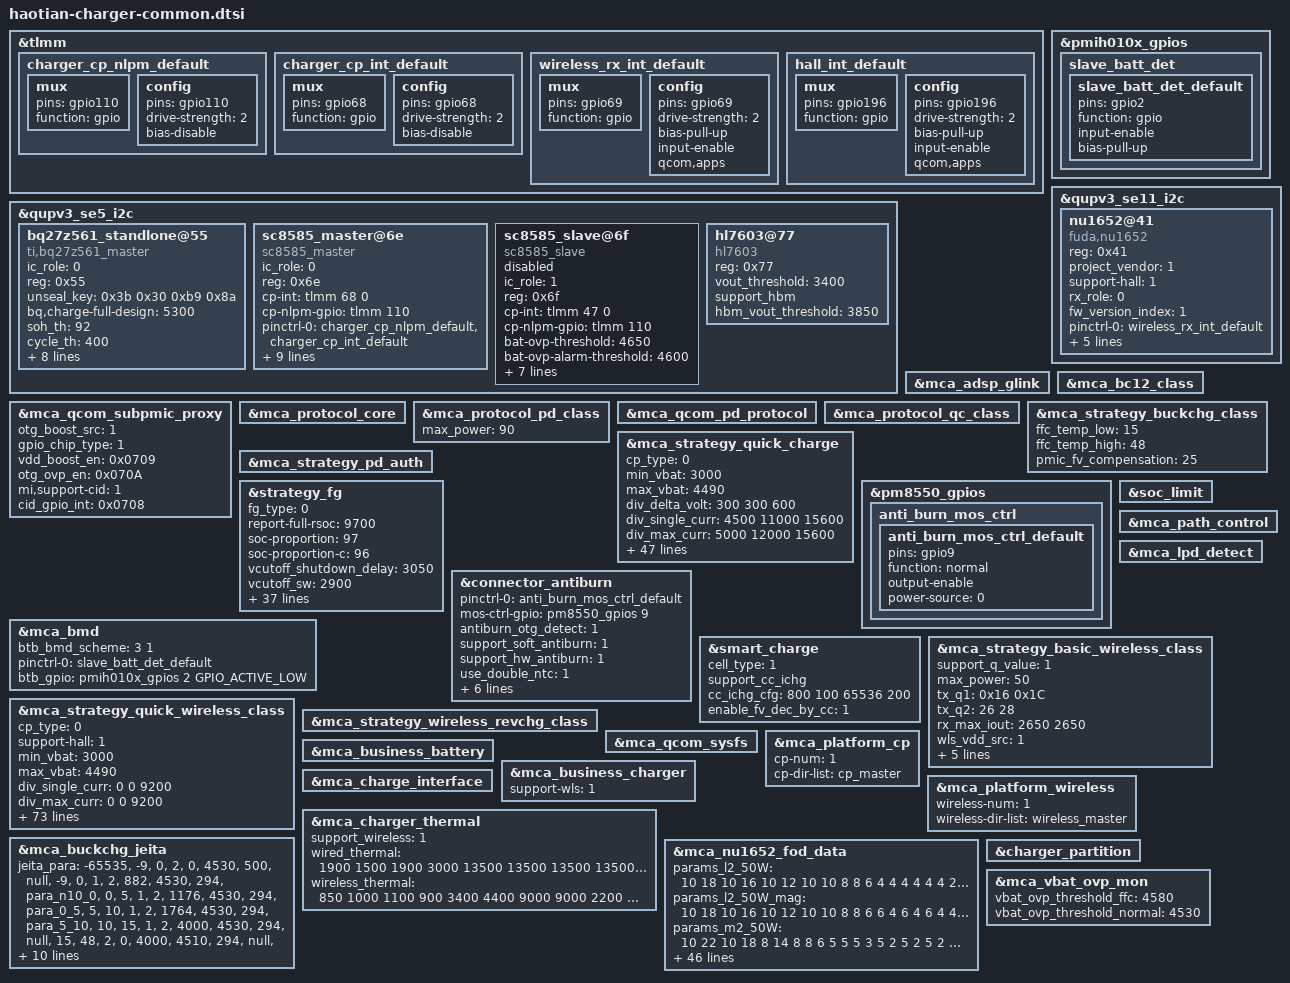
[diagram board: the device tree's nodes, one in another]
#include "mca.dtsi"

&tlmm {
	charger_cp_nlpm_default: charger_cp_nlpm_default {
		mux {
			pins = "gpio110";
			function = "gpio";
		};
		config {
			pins = "gpio110";
			drive-strength = <2>;   /* 2 mA */
			bias-disable;
		};
	};

	charger_cp_int_default: charger_cp_int_default {
		mux {
			pins = "gpio68";
			function = "gpio";
		};
		config {
			pins = "gpio68";
			drive-strength = <2>;   /* 2 mA */
			bias-disable;
		};
	};

	wireless_rx_int_default: wireless_rx_int_default {
		mux {
			pins = "gpio69";
			function = "gpio";
		};

		config {
			pins = "gpio69";
			drive-strength = <2>;
			bias-pull-up;
			input-enable;
			qcom,apps;
		};
	};

	hall_int_default: hall_int_default {
		mux {
			pins = "gpio196";
			function = "gpio";
		};

		config {
			pins = "gpio196";
			drive-strength = <2>;
			bias-pull-up;
			input-enable;
			qcom,apps;
		};
	};
};

&pmih010x_gpios {
	slave_batt_det {
		slave_batt_det_default: slave_batt_det_default {
			pins = "gpio2";
			function = "gpio";
			input-enable;
			bias-pull-up;
		};
	};
};


&qupv3_se5_i2c {
	status = "ok";
	#address-cells = <1>;
	#size-cells = <0>;
	bq27z561_standlone@55 {
		compatible = "ti,bq27z561_master";
		ic_role = <0>;
		reg = <0x55>;
		unseal_key = /bits/ 8 <0x3b 0x30 0xb9 0x8a>;
		bq,charge-full-design = <5300>;
		soh_th = <92>;
		cycle_th = <400>;
		cycle_step = <50>;
		resistance-id = <100000>;
		support-voltage-record-level;
		version_number = /bits/ 8 <0x44>;
		start_byte_address = /bits/ 8 <8>;
		byte_length = /bits/ 8 <8>;
		record_voltage = /bits/ 8 <0x86 0x0B 0x4E 0x0C 0x0C 0x0D 0x88 0x13>;
		status = "ok";
	};

	sc8585_master@6e {
		compatible = "sc8585_master";
		status = "ok";
		ic_role = <0>;
		reg = <0x6e>;
		cp-int= <&tlmm 68 0>;
		cp-nlpm-gpio = <&tlmm 110 0x00>;
		pinctrl-names = "default";
		pinctrl-0 = <&charger_cp_nlpm_default>, <&charger_cp_int_default>;
		bat-ovp-threshold = <4700>;
		bat-ovp-alarm-threshold = <4650>;
		bus-ovp-threshold = <21000 12000 6000>;
		usb-ovp-threshold = <21000 14000 7500>;
		bus-ocp-threshold = <5000 5500 5000>;
		wpc-ovp-threshold = <21000>;
		out-ovp-threshold = <5000>;
		pmid2-uvp-threshold = <100>;
		pmid2-ovp-threshold = <600>;
	};

	sc8585_slave@6f {
		compatible = "sc8585_slave";
		status = "disabled"; // O2 changed to use one cp since P1.1
		ic_role = <1>;
		reg = <0x6f>;
		cp-int= <&tlmm 47 0>;
		cp-nlpm-gpio = <&tlmm 110 0x00>;
		bat-ovp-threshold = <4650>;
		bat-ovp-alarm-threshold = <4600>;
		bus-ovp-threshold = <21000 12000 6000>;
		usb-ovp-threshold = <21000 14000 7500>;
		bus-ocp-threshold = <3500 5000 3500>;
		wpc-ovp-threshold = <21000>;
		out-ovp-threshold = <5000>;
		pmid2-uvp-threshold = <100>;
		pmid2-ovp-threshold = <600>;
	};

	hl7603@77 {
		compatible = "hl7603";
		reg = <0x77>;
		vout_threshold = <3400>;
		support_hbm;
		hbm_vout_threshold = <3850>;
	};
};

&qupv3_se11_i2c {
	status = "ok";
	#address-cells = <1>;
	#size-cells = <0>;
	nu1652@41 {
		compatible = "fuda,nu1652";
		reg = <0x41>;
		project_vendor = <1>;
		support-hall = <1>;
		rx_role = <0>;
		fw_version_index = <1>;
		pinctrl-names = "rx_int_pull_up", "hall_int_pull_up";
		pinctrl-0 = <&wireless_rx_int_default>;
		pinctrl-1 = <&hall_int_default>;
		rx-int = <&tlmm 69 0x00>;
		pwr-det-int = <&tlmm 81 0x00>;
		sleep-rx-gpio = <&tlmm 94 0x00>;
		hall-int2 = <&tlmm 196 0x00>;
	};
};

&mca_adsp_glink {
	status = "ok";
};

&mca_bc12_class {
	status = "ok";
};

&mca_qcom_subpmic_proxy {
	status = "ok";
	otg_boost_src = <1>;
	gpio_chip_type = <1>;
	vdd_boost_en = <0x0709>;
	otg_ovp_en = <0x070A>;
	mi,support-cid = <1>;
	cid_gpio_int = <0x0708>;
};

&mca_protocol_core {
	status = "ok";
};

&mca_protocol_pd_class {
	status = "ok";
	max_power = <90>;
};

&mca_qcom_pd_protocol {
	status = "ok";
};

&mca_protocol_qc_class {
	status = "ok";
};

&mca_strategy_buckchg_class {
	status = "ok";
	ffc_temp_low = <15>;
	ffc_temp_high = <48>;
	pmic_fv_compensation = <25>;
};

&mca_strategy_quick_charge {
	status = "ok";
	cp_type = <0>;
	min_vbat = <3000>;
	max_vbat = <4490>;
	div_delta_volt = <300 300 600>;
	div_single_curr = <4500 11000 15600>;
	div_max_curr = <5000 12000 15600>;
	ibus_compensation = <600 300 200>;
	max_power = <90000>;
	qc_normal_charge_fv = <4510>;
	pps_taper_vol_hys = <2>;
	pps_taper_fcc_thr = <2100>;
	hardware_cv = <1>;
	support_mode = <6>;
	support_cp_vfc = <1>;
	support_curr_monitor = <1>;
	curr_monitor_time_s = <130>;

	vstep_para =
		"1", "2000", "2",
		"2", "2000", "4",
		"4", "8000", "20",
		"4", "4000", "15",
		"4", "1500", "5",
		"4", "1000", "2",
		"4", "600", "2";

	batt_para =
		"0", "atl", "batt_para_atl",
		"0", "lwn", "batt_para_lwn";

	/* -------------------- batt_para_atl start -------------------- */
	/* temp_low, temp_high, low_temp_hys, high_temp_hys, max_current, volt_para_name stage_para_name */
	batt_para_atl =
		"-65535", "10", "0", "0", "0", "4100", "4100", "null", "null", "null", "null",
		"10", "15", "0", "0", "7056", "4530", "4530", "normal_para_atl_10_15", "null", "null", "null",
		"15", "48", "2", "2", "15600", "4510", "4580", "normal_para_atl_15_48", "ffc_para_atl_15_48", "null", "ffc_stage_atl_15_48",
		"48", "65535", "0", "0", "0", "4100", "4100", "null", "null", "null", "null";

	normal_para_atl_10_15 =
		"4200", "7056", "5880",
		"4523", "5880", "800";

	normal_para_atl_15_48 =
		"4270", "15600", "7056",
		"4503", "7056", "800";
	ffc_para_atl_15_48 =
		"4270", "15600", "12400",
		"4300", "12400", "10584",
		"4400", "10584", "8820",
		"4500", "8820", "7056",
		"4573", "7056", "2000";
	ffc_stage_atl_15_48 = <0 0 0 0 0 0 0 0 0 0>;
	/* -------------------- batt_para_atl end -------------------- */

	/* -------------------- batt_para_lwn start -------------------- */
	/* temp_low, temp_high, low_temp_hys, high_temp_hys, max_current, volt_para_name stage_para_name */
	batt_para_lwn =
		"-65535", "10", "0", "0", "0", "4100", "4100", "null", "null", "null", "null",
		"10", "15", "0", "0", "7056", "4530", "4530", "normal_para_lwn_10_15", "null", "null", "null",
		"15", "48", "2", "2", "15600", "4510", "4580", "normal_para_lwn_15_48", "ffc_para_lwn_15_48", "null", "ffc_stage_lwn_15_48",
		"48", "65535", "0", "0", "0", "4100", "4100", "null", "null", "null", "null";

	normal_para_lwn_10_15 =
		"4200", "7056", "5880",
		"4523", "5880", "800";

	normal_para_lwn_15_48 =
		"4210", "15600", "7056",
		"4503", "7056", "800";
	ffc_para_lwn_15_48 =
		"4210", "15600", "12400",
		"4300", "12400", "10584",
		"4400", "10584", "8820",
		"4500", "8820", "7056",
		"4573", "7056", "2000";
	ffc_stage_lwn_15_48 = <0 0 0 0 0 0 0 0 0 0>;
	/* -------------------- batt_para_lwn end -------------------- */
};

&mca_strategy_pd_auth {
	status = "ok";
};


&strategy_fg {
	status = "ok";
	fg_type = <0>;
	report-full-rsoc = <9700>;
	soc-proportion = <97>;
	soc-proportion-c = <96>;
	vcutoff_shutdown_delay = <3050>;
	vcutoff_sw = <2900>;
	vcutoff_fw = <3050>;
	support-vpack-low-shutdown;
	support-cc-vcutoff;
	/*temp_low, temp_high, low_temp_hys, high_temp_hys, vterm_para_name*/
	cc_vcutoff_cfg =
		"-65535", "0", "0", "2", "cc_para0",
		"0", "65535", "2", "0", "cc_para1";
	cc_para0 =
		"600", "2900", "2850", "2750",
		"1200", "3150", "3100", "2900",
		"65535", "3250", "3200","2900";
	cc_para1 =
		"200", "2900", "2850", "2750",
		"600", "3050", "3050", "2900",
		"1200", "3250", "3250", "2900",
		"65535", "3340", "3340", "2900";
	support-dod-vcutoff;
	weight = <36 21 14>;
	/*temp_low, temp_high, low_temp_hys, high_temp_hys, vterm_para_name*/
	dod_vcutoff_cfg =
		"-65535", "-6", "0", "2", "dod_para0",
		"-6", "0", "2", "2", "dod_para1",
		"0", "10", "2", "2", "dod_para2",
		"10", "60", "2", "2", "dod_para3",
		"60", "65535", "2", "0", "dod_para4";
	/*dod_count, vterm_fw, vterm_shutdown_delay, vempty*/
	dod_para0 =
		"32", "2900", "2850", "2750",
		"146", "2950", "2900", "2800",
		"176", "3050", "3000", "2900",
		"65535", "3150", "3100", "2900";
	dod_para1 =
		"32", "2900", "2850","2750",
		"146", "3050", "3000","2900",
		"176", "3150", "3100","2900",
		"65535", "3250", "3250","2900";
	dod_para2 =
		"14", "2900", "2850","2750",
	 	"32", "3050", "3050","2900",
		"146", "3150", "3150","2900",
		"176", "3250", "3250","2900",
		"65535", "3340", "3340","2900";
	dod_para3 =
		"14", "2900", "2850","2750",
	 	"32", "3050", "3050","2900",
		"146", "3250", "3250","2900",
		"176", "3340", "3340","2900",
		"65535", "3400", "3400","2900";
	dod_para4 =
		"65535", "3430", "3430","2900";
	adapt_power = <90>;
	model-name = "O2_6100mah_90w";
	model-name-global = "O2_6100mah_90w";
	charge-full-design = <6100>;
	charge-full-design-gl = <6100>;
	support_dtpt = <1>;
	support-lossless-rechg = <1>;
	lossless_rechg_cfg = <15 47 300>;
};

&pm8550_gpios {
        anti_burn_mos_ctrl {
                anti_burn_mos_ctrl_default: anti_burn_mos_ctrl_default {
                        pins = "gpio9";
                        function = "normal";
                        output-enable;
                        //drive-strength = <2>;
                        power-source = <0>;
                };
        };
};

&connector_antiburn {
	status = "ok";
	pinctrl-names = "default";
	pinctrl-0 = <&anti_burn_mos_ctrl_default>;
	mos-ctrl-gpio = <&pm8550_gpios 9 0>;
	antiburn_otg_detect = <1>;
	support_soft_antiburn = <1>;
	support_hw_antiburn = <1>;
	use_double_ntc = <1>;
	monitor_interval = <1000>;
	thermal-zone-name = "conn_therm";
	thermal-zone-name2 = "conn_therm2";
	max_temp_increase_rate = <4>; /*ntc temperature increase speed per second.*/
	otg_boost_src = <2>;   //BOOST_SRC_EXTERNAL
	en_src = <0>;      //OTG_EN_BOOST
        //thermal-board-temp-name = "board_sensor_therm";
};

&mca_bmd {
	status = "ok";
	btb_bmd_scheme = <3 1>;
	pinctrl-names = "default";
	pinctrl-0 = <&slave_batt_det_default>;
	btb_gpio = <&pmih010x_gpios 2 GPIO_ACTIVE_LOW>;
};

&smart_charge {
	status = "ok";
	cell_type = <1>;
	support_cc_ichg;
	cc_ichg_cfg = </* cyclecount delta_ichg*/
	800 100
	65536 200>;
	enable_fv_dec_by_cc = <1>;
};

&soc_limit {
	status = "ok";
};

&mca_path_control {
	status = "ok";
};

&mca_lpd_detect {
	status = "ok";
};

&mca_strategy_basic_wireless_class {
	status = "ok";
	support_q_value = <1>;
	max_power = <50>;
	//low_inductance_tx_50w, low_inductance_tx_80w
	tx_q1 = /bits/ 8 <0x16 0x1C>;
	tx_q2 = <26 28>;
	rx_max_iout = <2650 2650>;
	wls_vdd_src = <1>;
	ffc_temp_low = <15>;
	ffc_temp_high = <48>;
	support-hall = <1>;
	phone_icl = <150>;
	pmic_fv_compensation = <15>;
};

&mca_strategy_quick_wireless_class {
	status = "ok";
	cp_type = <0>;
	support-hall = <1>;
	min_vbat = <3000>;
	max_vbat = <4490>;
	div_single_curr = <0 0 9200>;
	div_max_curr = <0 0 9200>;
	batt_para =
		"0", "atl", "batt_para_atl",
		"0", "lwn", "batt_para_lwn";

	/* -------------------- batt_para_atl start -------------------- */
	/* temp_low, temp_high, low_temp_hys, high_temp_hys, max_current, volt_para_name stage_para_name */
	batt_para_atl =
		"-65535", "10", "0", "0", "0", "4100", "4100", "null", "null", "null", "null",
		"10", "15", "0", "0", "7056", "4530", "4530", "normal_para_atl_10_15", "null", "null", "null",
		"15", "35", "2", "2", "15600", "4510", "4580", "normal_para_atl_15_35", "ffc_para_atl_15_35", "null", "ffc_stage_atl_15_35",
		"35", "40", "2", "2", "15600", "4510", "4580", "normal_para_atl_35_40", "ffc_para_atl_35_40", "null", "ffc_stage_atl_35_40",
		"40", "48", "2", "2", "15600", "4510", "4580", "normal_para_atl_40_48", "ffc_para_atl_40_48", "null", "ffc_stage_atl_40_48",
		"48", "65535", "0", "0", "0", "4100", "4100", "null", "null", "null", "null";

	normal_para_atl_10_15 =
		"4200", "7056", "5880",
		"4530", "5880", "800";

	normal_para_atl_15_35 =
		"4270", "15600", "7056",
		"4510", "7056", "800";
	ffc_para_atl_15_35 =
		"4270", "15600", "12400",
		"4300", "12400", "10584",
		"4400", "10584", "8820",
		"4500", "8820", "7056",
		"4570", "7056", "2300";
	ffc_stage_atl_15_35 = <0 1 0 0 0 0 0 0 0 0>;

	normal_para_atl_35_40 =
		"4270", "15600", "7056",
		"4510", "7056", "800";
	ffc_para_atl_35_40 =
		"4270", "15600", "12400",
		"4300", "12400", "10584",
		"4400", "10584", "8820",
		"4500", "8820", "7056",
		"4570", "7056", "3000";
	ffc_stage_atl_35_40 = <0 1 0 0 0 0 0 0 0 0>;

	normal_para_atl_40_48 =
		"4270", "15600", "7056",
		"4510", "7056", "800";
	ffc_para_atl_40_48 =
		"4270", "15600", "12400",
		"4300", "12400", "10584",
		"4400", "10584", "8820",
		"4500", "8820", "7056",
		"4570", "7056", "3000";
	ffc_stage_atl_40_48 = <0 1 0 0 0 0 0 0 0 0>;
	/* -------------------- batt_para_atl end -------------------- */

	/* -------------------- batt_para_lwn start -------------------- */
	/* temp_low, temp_high, low_temp_hys, high_temp_hys, max_current, volt_para_name stage_para_name */
	batt_para_lwn =
		"-65535", "10", "0", "0", "0", "4100", "4100", "null", "null", "null", "null",
		"10", "15", "0", "0", "7056", "4530", "4530", "normal_para_lwn_10_15", "null", "null", "null",
		"15", "35", "2", "2", "15600", "4510", "4580", "normal_para_lwn_15_35", "ffc_para_lwn_15_35", "null", "ffc_stage_lwn_15_35",
		"35", "40", "2", "2", "15600", "4510", "4580", "normal_para_lwn_35_40", "ffc_para_lwn_35_40", "null", "ffc_stage_lwn_35_40",
		"40", "48", "2", "2", "15600", "4510", "4580", "normal_para_lwn_40_48", "ffc_para_lwn_40_48", "null", "ffc_stage_lwn_40_48",
		"48", "65535", "0", "0", "0", "4100", "4100", "null", "null", "null", "null";

	normal_para_lwn_10_15 =
		"4200", "7056", "5880",
		"4530", "5880", "800";

	normal_para_lwn_15_35 =
		"4210", "15600", "7056",
		"4510", "7056", "800";
	ffc_para_lwn_15_35 =
		"4210", "15600", "12400",
		"4300", "12400", "10584",
		"4400", "10584", "8820",
		"4500", "8820", "7056",
		"4570", "7056", "2300";
	ffc_stage_lwn_15_35 = <0 1 0 0 0 0 0 0 0 0>;

	normal_para_lwn_35_40 =
		"4210", "15600", "7056",
		"4510", "7056", "800";
	ffc_para_lwn_35_40 =
		"4210", "15600", "12400",
		"4300", "12400", "10584",
		"4400", "10584", "8820",
		"4500", "8820", "7056",
		"4570", "7056", "3000";
	ffc_stage_lwn_35_40 = <0 1 0 0 0 0 0 0 0 0>;

	normal_para_lwn_40_48 =
		"4210", "15600", "7056",
		"4510", "7056", "800";
	ffc_para_lwn_40_48 =
		"4210", "15600", "12400",
		"4300", "12400", "10584",
		"4400", "10584", "8820",
		"4500", "8820", "7056",
		"4570", "7056", "3000";
	ffc_stage_lwn_40_48 = <0 1 0 0 0 0 0 0 0 0>;
	/* -------------------- batt_para_lwn end -------------------- */

	vstep_para =
		"1", "2000", "2",
		"2", "2000", "4",
		"4", "4000", "25",
		"4", "3000", "25",
		"4", "2000", "6",
		"4", "1000", "3",
		"4", "500", "2",
		"4", "200", "1";
};

&mca_strategy_wireless_revchg_class{
	status = "ok";
};

&mca_qcom_sysfs {
	status = "ok";
};

&mca_business_battery {
	status = "ok";
};

&mca_business_charger {
	support-wls = <1>;
	status = "ok";
};

&mca_platform_cp {
	status = "ok";
	cp-num = <1>;
	cp-dir-list = "cp_master";
};

&mca_platform_wireless {
	status = "ok";
	wireless-num = <1>;
	wireless-dir-list = "wireless_master";
};

&mca_charge_interface
{
	status = "ok";
};

&mca_charger_thermal
{
	status = "ok";
	support_wireless = <1>;
	// wired_sic_select = "atl", "lwn";
	/* 5v_in 9v_in 5v_ichg 9v_ichg div1_single div1_multi div2_single div2_multi div4_single div4_multi*/
	wired_thermal = <
		1900 1500 1900 3000 13500 13500 13500 13500 13500 13500 /* level 1 */
		1900 1500 1900 3000 11000 11000 11000 11000 11000 11000 /* level 2 */
		1900 1500 1900 3000 9000  9000  9000  9000  9000  9000  /* level 3 */
		1900 1450 1900 3000 8000  8000  8000  8000  8000  8000  /* level 4 */
		1900 1400 1900 3000 7000  7000  7000  7000  7000  7000  /* level 5 */
		1900 1350 1900 2800 6000  6000  6000  6000  6000  6000  /* level 6 */
		1900 1300 1900 2600 5000  5000  5000  5000  5000  5000  /* level 7 */
		1900 1150 1900 2310 4000  4000  4000  4000  4000  4000  /* level 8 */
		1700 1100 1700 2200 3500  3500  3500  3500  3500  3500  /* level 9 */
		1600 1000 1600 2000 3000  3000  3000  3000  3000  3000  /* level 10 */
		1400 900  1500 2000 2500  2500  2500  2500  2500  2500  /* level 11 */
		1200 850  1500 2000 2000  2000  2000  2000  2000  2000  /* level 12 */
		1100 750  1500 1500 1500  1500  1500  1500  1500  1500  /* level 13 */
		1100 650  1000 1000 1000  1000  1000  1000  1000  1000  /* level 14 */
		1100 600  500  500  500   500   500   500   500   500   /* level 15 */
	>;
	/* bpp_in bpp_qc2 bpp_qc3 epp_in cp_20w cp_30w cp_50w cp_80w voice_box magnet_30w*/
	wireless_thermal = <
	850 1000 1100 900 3400 4400 9000 9000 2200 4400 /* level 1 */
	850 1000 1100 750 3200 4200 6800 8000 2200 4200 /* level 2 */
	850 1000 1100 650 2200 3400 5800 7000 1000 3400 /* level 3 */
	700 1000 1100 650 1800 2800 4800 6000 1000 2800 /* level 4 */
	700 1000  700 650 1500 2600 4200 5000  800 2600 /* level 5 */
	500 1000  700 650 1300 2200 3900 4000  800 2200 /* level 6 */
	500  700  600 400 1100 2200 3500 3500  700 2200 /* level 7 */
	500  700  600 400 1000 1800 3000 3000  700 1800 /* level 8 */
	500  500  500 300  800 1100 2500 2500  600 1100 /* level 9 */
	400  500  500 300  700 1000 2000 2000  600 1000 /* level 10 */
	400  500  500 250  600  800 1500 1500  500  800 /* level 11 */
	400  500  500 250  500  700 1000 1000  500  700 /* level 12 */
	300  500  500 250  500  600  800  800  400  600  /* level 13 */
	300  400  400 200  400  500  500  500  400  500  /* level 14 */
	300  300  300 150  300  400  400  400  300  400  /* level 15 */
	>;
};

&mca_buckchg_jeita
{
	status = "ok";

	/* temp_low, temp_high, low_temp_hys, high_temp_hys, max_current, vterm, iterm volt_para_name */
	jeita_para =
		"-65535", "-9", "0", "2", "0", "4530", "500", "null",
		"-9", "0", "1", "2", "882", "4530", "294", "para_n10_0",
		"0", "5", "1", "2", "1176", "4530", "294", "para_0_5",
		"5", "10", "1", "2", "1764", "4530", "294", "para_5_10",
		"10", "15", "1", "2", "4000", "4530", "294", "null",
		"15", "48", "2", "0", "4000", "4510", "294", "null",
		"48", "55", "2", "2", "2940", "4060", "294", "null",
		"55", "65535", "2", "2", "0", "4060", "230", "null";
	para_n10_0 =
		"4200", "882",
		"4530", "588";
	para_0_5 =
		"4200", "1176",
		"4530", "882";
	para_5_10 =
		"4200", "1764",
		"4530", "1176";

	jeita_para_ffc =
		"15", "35", "2", "2", "4000", "4580", "1529", "null",
		"35", "40", "2", "2", "4000", "4580", "1764", "null",
		"40", "48", "2", "0", "4000", "4580", "2058", "null",
		"48", "55", "2", "2", "2940", "4060", "294", "null",
		"55", "65535", "2", "2", "0", "4060", "230", "null";
};

&mca_nu1652_fod_data
{
	params_l2_50W = /bits/ 8 <
			10 18
			10 16
			10 12
			10 10
			8  8
			6  4
			4  4
			4  4
			4  2
			3  0
			3  0
			3  0
	>;
	params_l2_50W_mag = /bits/ 8 <
			10 18
			10 16
			10 12
			10 10
			8  8
			6  6
			4  6
			4  6
			4  4
			3  2
			3  0
			3  0
	>;

	params_m2_50W = /bits/ 8 <
		10 22
		10 18
		8  14
		8  8
		6  5
		5  5
		3  5
		2  5
		2  5
		2  7
		2  7
		2  7
	>;
	params_m2_50W_mag = /bits/ 8 <
		12 22
		12 18
		12 14
		12 10
		6  8
		6  6
		4  8
		3  8
		3  10
		3  10
		3  10
		3  10
	>;

	params_j1s_55W = /bits/ 8 <
		10 20
		10 18
		10 12
		10 10
		8  8
		6  4
		4  4
		4  4
		4  2
		3  0
		3  0
		3  0
	>;
	params_j1s_55W_mag = /bits/ 8 <
		10 20
		10 18
		10 12
		10 10
		8  8
		6  4
		4  4
		4  4
		4  2
		3  0
		3  0
		3  0
	>;

	params_magnet_30W = /bits/ 8 <
		16 15
		16 15
		16 15
		16 15
		16 15
		16 15
		16 15
		16 15
		16 15
		16 15
		16 15
		16 15
	>;
	params_magnet_30W_mag = /bits/ 8 <
		14 15
		14 12
		14 12
		13 12
		13 12
		13 12
		13 12
		13 12
		13 12
		13 12
		13 12
		13 12
	>;

	params_redmi_disc_30W = /bits/ 8 <
		10 12
		10 12
		10 8
		8  6
		7  4
		7  2
		7  2
		7  2
		7  2
		7  2
		7  2
		7  2
	>;
	params_redmi_disc_30W_mag = /bits/ 8 <
		10 12
		10 12
		10 8
		8  6
		7  4
		7  2
		7  2
		7  2
		7  2
		7  2
		7  2
		7  2
	>;

	params_k8_100W = /bits/ 8 <
		10 20
		10 16
		10 12
		10 10
		10 6
		10 5
		8  5
		7  5
		6  5
		5  5
		5  5
		5  5
	>;
	params_k8_100W_mag = /bits/ 8 <
		10 20
		10 16
		10 12
		10 10
		10 6
		10 5
		8  5
		7  5
		6  5
		5  5
		5  5
		5  5
	>;

	params_k1_80W = /bits/ 8 <
		12 18
		12 16
		12 12
		12 8
		12 6
		9  5
		8  5
		7  5
		5  5
		5  4
		5  4
		5  4
	>;
	params_k1_80W_mag = /bits/ 8 <
		12 18
		12 16
		12 12
		12 8
		12 6
		9  5
		8  5
		7  5
		5  5
		5  4
		5  4
		5  4
	>;

	params_n1_80W = /bits/ 8 <
		4 12
		4 8
		2 4
		2 4
		2 6
		1 6
		1 6
		1 7
		1 7
		1 7
		1 7
		1 7
	>;
	params_n1_80W_mag = /bits/ 8 <
		4 12
		4 8
		2 7
		2 7
		2 7
		1 7
		1 7
		1 7
		1 7
		1 7
		1 7
		1 7
	>;

	params_double_coil_30W = /bits/ 8 <
		10 10
		10 10
		10 8
		10 9
		10 9
		10 9
		10 9
		10 9
		10 9
		10 9
		10 9
		10 9
	>;
	params_double_coil_30W_mag = /bits/ 8 <
		10 10
		10 10
		10 8
		10 9
		10 9
		10 9
		10 9
		10 9
		10 9
		10 9
		10 9
		10 9
	>;

	params_white_stand_30W = /bits/ 8 <
		10 18
		10 16
		10 14
		10 10
		8  6
		7  4
		7  4
		7  4
		7  4
		7  4
		7  4
		7  4
	>;
	params_white_stand_30W_mag = /bits/ 8 <
		10 18
		10 16
		10 14
		10 10
		8  6
		7  4
		7  4
		7  4
		7  4
		7  4
		7  4
		7  4
	>;

	params_zimi_20W = /bits/ 8 <
		10 20
		10 18
		10 18
		10 16
		10 16
		10 16
		10 16
		10 10
		10 10
		10 10
		10 10
		10 10
	>;
	params_zimi_20W_mag = /bits/ 8 <
		10 20
		10 18
		10 18
		10 16
		10 16
		10 16
		10 16
		10 10
		10 10
		10 10
		10 10
		10 10
	>;

	params_moving_20W = /bits/ 8 <
		10 16
		10 14
		10 10
		8  8
		8  8
		8  8
		8  8
		8  8
		8  8
		8  8
		8  8
		8  8
	>;
	params_moving_20W_mag = /bits/ 8 <
		10 16
		10 14
		10 10
		8  8
		8  8
		8  8
		8  8
		8  8
		8  8
		8  8
		8  8
		8  8
	>;

	params_multcoil_20W = /bits/ 8 <
		10  20
		10  18
		10  16
		10  16
		10  16
		10  16
		10  16
		10  16
		10  16
		10  16
		10  16
		10  16
	>;
	params_multcoil_20W_mag = /bits/ 8 <
		10  20
		10  18
		10  16
		10  16
		10  16
		10  16
		10  16
		10  16
		10  16
		10  16
		10  16
		10  16
	>;
};

&charger_partition
{
	status = "ok";
};

&mca_vbat_ovp_mon {
	vbat_ovp_threshold_ffc = <4580>;
	vbat_ovp_threshold_normal = <4530>;
	status = "ok";
};
